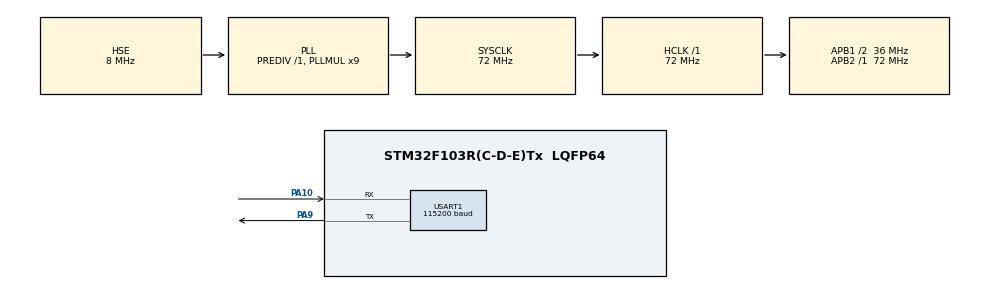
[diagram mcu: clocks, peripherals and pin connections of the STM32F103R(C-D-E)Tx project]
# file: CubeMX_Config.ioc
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Mcu.Family=STM32F1
Mcu.Name=STM32F103R(C-D-E)Tx
Mcu.Package=LQFP64
NVIC.PriorityGroup=NVIC_PRIORITYGROUP_4
NVIC.USART1_IRQn=true\:0\:0\:false\:false\:true\:true\:true\:true
PA10.GPIO_PuPd=GPIO_PULLUP
PA10.Mode=Asynchronous
PA10.Signal=USART1_RX
PA13.Mode=Serial_Wire
PA13.Signal=SYS_JTMS-SWDIO
PA14.Mode=Serial_Wire
PA14.Signal=SYS_JTCK-SWCLK
PA9.Mode=Asynchronous
PA9.Signal=USART1_TX
PD0-OSC_IN.Mode=HSE-External-Oscillator
PD0-OSC_IN.Signal=RCC_OSC_IN
PD1-OSC_OUT.Mode=HSE-External-Oscillator
PD1-OSC_OUT.Signal=RCC_OSC_OUT
ProjectManager.HeapSize=0x200
ProjectManager.StackSize=0x400
ProjectManager.TargetToolchain=MDK-ARM V5
RCC.AHBFreq_Value=72000000
RCC.APB1CLKDivider=RCC_HCLK_DIV2
RCC.APB1Freq_Value=36000000
RCC.APB1TimFreq_Value=72000000
RCC.APB2Freq_Value=72000000
RCC.APB2TimFreq_Value=72000000
RCC.FLatency=FLASH_LATENCY_2
RCC.HCLKFreq_Value=72000000
RCC.PLLMUL=RCC_PLL_MUL9
RCC.PLLSourceVirtual=RCC_PLLSOURCE_HSE
RCC.SYSCLKFreq_VALUE=72000000
RCC.SYSCLKSource=RCC_SYSCLKSOURCE_PLLCLK
RCC.USBFreq_Value=72000000
USART1.BaudRate=115200
USART1.Mode=MODE_TX_RX
USART1.Parity=PARITY_NONE
USART1.StopBits=STOPBITS_1
USART1.VirtualMode=VM_ASYNC
USART1.WordLength=WORDLENGTH_8B
board=custom

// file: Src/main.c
/* USER CODE BEGIN Header */
/**
  ******************************************************************************
  * @file           : main.c
  * @brief          : Main program body
  ******************************************************************************
  * @attention
  *
  * Copyright (c) 2024 STMicroelectronics.
  * All rights reserved.
  *
  * This software is licensed under terms that can be found in the LICENSE file
  * in the root directory of this software component.
  * If no LICENSE file comes with this software, it is provided AS-IS.
  *
  ******************************************************************************
  */
/* USER CODE END Header */
#include "main.h"
#include "usart.h"
#include "delay.h"
#include "sys.h"
#include "FreeRTOS.h"
#include "task.h"

/* USER CODE BEGIN Includes */

TaskHandle_t myTaskHandler;
void myTask(void *argument);
/* USER CODE END Includes */

UART_HandleTypeDef huart1;

void SystemClock_Config(void);
static void MX_GPIO_Init(void);
static void MX_USART1_UART_Init(void);

int main(void)
{

  /* MCU Configuration--------------------------------------------------------*/

  /* Reset of all peripherals, Initializes the Flash interface and the Systick. */
  HAL_Init();

  /* Configure the system clock */
  SystemClock_Config();

  /* Initialize all configured peripherals */
  MX_GPIO_Init();
  MX_USART1_UART_Init();

  /* Infinite loop */
  /* USER CODE BEGIN WHILE */
	delay_init(72);
	uart_init(115200);
	xTaskCreate(myTask,"myTask",512,NULL,2,&myTaskHandler);
  vTaskStartScheduler();
  while (1)
  {
    /* USER CODE END WHILE */
  }
}

void SystemClock_Config(void)
{
  RCC_OscInitTypeDef RCC_OscInitStruct = {0};
  RCC_ClkInitTypeDef RCC_ClkInitStruct = {0};

  /** Initializes the RCC Oscillators according to the specified parameters
  * in the RCC_OscInitTypeDef structure.
  */
  RCC_OscInitStruct.OscillatorType = RCC_OSCILLATORTYPE_HSE;
  RCC_OscInitStruct.HSEState = RCC_HSE_ON;
  RCC_OscInitStruct.HSEPredivValue = RCC_HSE_PREDIV_DIV1;
  RCC_OscInitStruct.HSIState = RCC_HSI_ON;
  RCC_OscInitStruct.PLL.PLLState = RCC_PLL_ON;
  RCC_OscInitStruct.PLL.PLLSource = RCC_PLLSOURCE_HSE;
  RCC_OscInitStruct.PLL.PLLMUL = RCC_PLL_MUL9;
  if (HAL_RCC_OscConfig(&RCC_OscInitStruct) != HAL_OK)
  {
    Error_Handler();
  }

  /** Initializes the CPU, AHB and APB buses clocks
  */
  RCC_ClkInitStruct.ClockType = RCC_CLOCKTYPE_HCLK|RCC_CLOCKTYPE_SYSCLK
                              |RCC_CLOCKTYPE_PCLK1|RCC_CLOCKTYPE_PCLK2;
  RCC_ClkInitStruct.SYSCLKSource = RCC_SYSCLKSOURCE_PLLCLK;
  RCC_ClkInitStruct.AHBCLKDivider = RCC_SYSCLK_DIV1;
  RCC_ClkInitStruct.APB1CLKDivider = RCC_HCLK_DIV2;
  RCC_ClkInitStruct.APB2CLKDivider = RCC_HCLK_DIV1;

  if (HAL_RCC_ClockConfig(&RCC_ClkInitStruct, FLASH_LATENCY_2) != HAL_OK)
  {
    Error_Handler();
  }
}

static void MX_USART1_UART_Init(void)
{

  huart1.Instance = USART1;
  huart1.Init.BaudRate = 115200;
  huart1.Init.WordLength = UART_WORDLENGTH_8B;
  huart1.Init.StopBits = UART_STOPBITS_1;
  huart1.Init.Parity = UART_PARITY_NONE;
  huart1.Init.Mode = UART_MODE_TX_RX;
  huart1.Init.HwFlowCtl = UART_HWCONTROL_NONE;
  huart1.Init.OverSampling = UART_OVERSAMPLING_16;
  if (HAL_UART_Init(&huart1) != HAL_OK)
  {
    Error_Handler();
  }

}

static void MX_GPIO_Init(void)
{

  /* GPIO Ports Clock Enable */
  __HAL_RCC_GPIOD_CLK_ENABLE();
  __HAL_RCC_GPIOA_CLK_ENABLE();

/* USER CODE BEGIN MX_GPIO_Init_2 */
    GPIO_InitTypeDef GPIO_Initure;
    __HAL_RCC_GPIOA_CLK_ENABLE();           	//开启GPIOA时钟
		__HAL_RCC_GPIOD_CLK_ENABLE();           	//开启GPIOD时钟
    GPIO_Initure.Pin=GPIO_PIN_8; 				//PB8
    GPIO_Initure.Mode=GPIO_MODE_OUTPUT_PP;  	//推挽输出
    GPIO_Initure.Pull=GPIO_PULLUP;          	//上拉
    GPIO_Initure.Speed=GPIO_SPEED_FREQ_HIGH;    //高速
    HAL_GPIO_Init(GPIOA,&GPIO_Initure);
		GPIO_Initure.Pin=GPIO_PIN_2; 				//PD2
		HAL_GPIO_Init(GPIOD,&GPIO_Initure);
    HAL_GPIO_WritePin(GPIOA,GPIO_PIN_8,GPIO_PIN_SET);	//PA8置1，默认初始化后灯灭
    HAL_GPIO_WritePin(GPIOD,GPIO_PIN_2,GPIO_PIN_SET);	//PD2置1，默认初始化后灯灭
/* USER CODE END MX_GPIO_Init_2 */
}

/* USER CODE BEGIN 4 */
void myTask(void *argument)
{
  for(;;)
  {
				printf("hello world!\r\n");
        HAL_GPIO_WritePin(GPIOA,GPIO_PIN_8,GPIO_PIN_RESET); 	//LED0对应引脚PA8拉低，亮，等同于LED0(0)
        HAL_GPIO_WritePin(GPIOD,GPIO_PIN_2,GPIO_PIN_SET);   	//LED1对应引脚PD2拉高，灭，等同于LED1(1)
        vTaskDelay(pdMS_TO_TICKS(500)); 										//延时500ms
        HAL_GPIO_WritePin(GPIOA,GPIO_PIN_8,GPIO_PIN_SET);   	//LED0对应引脚PA8拉高，灭，等同于LED0(1)
        HAL_GPIO_WritePin(GPIOD,GPIO_PIN_2,GPIO_PIN_RESET); 	//LED1对应引脚PD2拉低，亮，等同于LED1(0)
				vTaskDelay(pdMS_TO_TICKS(500));
  }
}
/* USER CODE END 4 */

void Error_Handler(void)
{
  __disable_irq();
  while (1)
  {
  }
}
